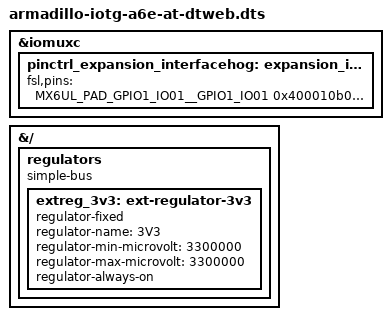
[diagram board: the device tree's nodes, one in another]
// SPDX-License-Identifier: (GPL-2.0 OR MIT)
/*
 * Copyright (C) 2022 Atmark Techno, Inc. All Rights Reserved.
 */

/dts-v1/;
/plugin/;

#include <dt-bindings/gpio/gpio.h>
#include <dt-bindings/clock/imx6ul-clock.h>
#include <dt-bindings/pwm/pwm.h>

#include "imx6ull-pinfunc.h"

&iomuxc {
	pinctrl_expansion_interfacehog: expansion_interfacehoggrp {
		fsl,pins = <
			/* CON8 */
											// CON8_1	VIN
											// CON8_2	GND
											// CON8_3	VCC_5V
											// CON8_4	GND
											// CON8_5	VCC_3.3V
											// CON8_6	GND
			MX6UL_PAD_GPIO1_IO01__GPIO1_IO01	0x400010b0 // CON8_7
			MX6UL_PAD_GPIO1_IO02__GPIO1_IO02	0x400010b0 // CON8_8
			MX6UL_PAD_GPIO1_IO03__GPIO1_IO03	0x400010b0 // CON8_9
			MX6UL_PAD_GPIO1_IO04__GPIO1_IO04	0x400010b0 // CON8_10
											// CON8_11	GND
											// CON8_12	I2C4_SCL
											// CON8_13	I2C4_SDA
			MX6UL_PAD_LCD_DATA00__GPIO3_IO05	0x400010b0 // CON8_14
			MX6UL_PAD_LCD_DATA01__GPIO3_IO06	0x400010b0 // CON8_15
			MX6UL_PAD_LCD_DATA02__GPIO3_IO07	0x400010b0 // CON8_16
			MX6UL_PAD_LCD_DATA03__GPIO3_IO08	0x400010b0 // CON8_17
											// CON8_18	GND
			MX6UL_PAD_LCD_DATA05__GPIO3_IO10	0x400010b0 // CON8_19
			MX6UL_PAD_LCD_DATA06__GPIO3_IO11	0x400010b0 // CON8_20
			MX6UL_PAD_LCD_DATA07__GPIO3_IO12	0x400010b0 // CON8_21
			MX6UL_PAD_LCD_DATA08__GPIO3_IO13	0x400010b0 // CON8_22
			MX6UL_PAD_LCD_DATA09__GPIO3_IO14	0x400010b0 // CON8_23
			MX6UL_PAD_LCD_DATA10__GPIO3_IO15	0x400010b0 // CON8_24
			MX6UL_PAD_LCD_DATA11__GPIO3_IO16	0x400010b0 // CON8_25
			MX6UL_PAD_LCD_DATA15__GPIO3_IO20	0x400010b0 // CON8_26
			MX6UL_PAD_LCD_DATA16__GPIO3_IO21	0x400010b0 // CON8_27
			MX6UL_PAD_LCD_DATA17__GPIO3_IO22	0x400010b0 // CON8_28
			MX6UL_PAD_CSI_DATA04__GPIO4_IO25	0x400010b0 // CON8_29
			MX6UL_PAD_CSI_DATA05__GPIO4_IO26	0x400010b0 // CON8_30
			MX6UL_PAD_CSI_DATA06__GPIO4_IO27	0x400010b0 // CON8_31
			MX6UL_PAD_CSI_DATA07__GPIO4_IO28	0x400010b0 // CON8_32
											// CON8_33	GND
											// CON8_34	GND
		>;
	};

};

&{/} {
	regulators {
		compatible = "simple-bus";
		#address-cells = <1>;
		#size-cells = <0>;

		extreg_3v3: ext-regulator-3v3 {
				compatible = "regulator-fixed";
				regulator-name = "3V3";
				regulator-min-microvolt = <3300000>;
				regulator-max-microvolt = <3300000>;
				regulator-always-on;
		};
	};

};
